# R7FA8M1AH register map
Vendor: Renesas; Series: RA8; File version: 1.2
CPU: CM85 r0p0, little endian, MPU, FPU, VTOR, 4 interrupt priority bits
Registers are 32-bit, read-write, reset 0x0 unless marked. A register's access mark holds for its fields unless they carry their own. Offsets are from the block's base; [hi:lo] are bit positions; {n}, {i} and the like mark numbered series.

## SRAM — SRAM Control
Base 0x40002000
Same registers: SRAM_NS 0x50002000
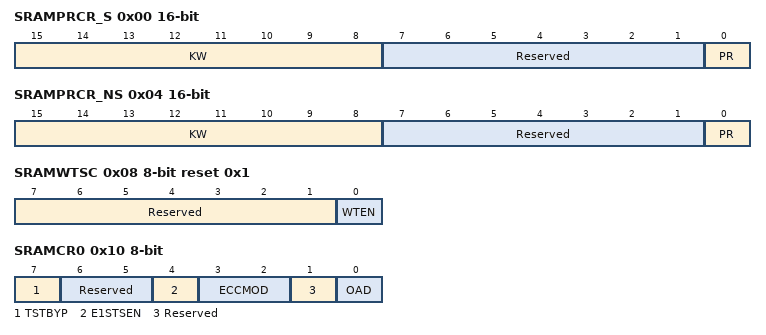
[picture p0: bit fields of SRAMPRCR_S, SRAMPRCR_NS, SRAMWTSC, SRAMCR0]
0x00 SRAMPRCR_S 16-bit — SRAM Protection Control Register for Secure
  [15:8] KW — Write Key Code
  [7:1] Reserved — These bits are read as 0000000. The write value should be 0000000.
  [0] PR — Register Write Control
    0=Accesses to registers are disabled; 1=Accesses to registers are enabled
0x04 SRAMPRCR_NS 16-bit — SRAM Protection Control Register for Non-Secure
  [15:8] KW — Write Key Code
  [7:1] Reserved — These bits are read as 0000000. The write value should be 0000000.
  [0] PR — Register Write Control
    0=Writing to registers are disabled; 1=Writing to registers are enabled
0x08 SRAMWTSC 8-bit reset 0x1 — SRAM Wait State Control Register
  [7:1] Reserved — These bits are read as 0000000. The write value should be 0000000.
  [0] WTEN — wait enable
    0=Do not add wait state in read access cycle to SRAMs; 1=Add wait state in read access cycle to SRAMs
0x10 SRAMCR0 8-bit — SRAM Control Register 0
  [7] TSTBYP — ECC Test Enable / ECC Bypass Select
    0=Disable ECC bypass; 1=Enable ECC bypass
  [6:5] Reserved — These bits are read as 00. The write value should be 00.
  [4] E1STSEN — ECC 1-Bit Error Information Update Enable
    0=Disable updating of 1-bit ECC error information; 1=Enable updating of 1-bit ECC error information
  [3:2] ECCMOD — ECC Operating Mode Select
    0=Disable ECC function; 1=Setting prohibited; 2=Enable ECC function without error checking; 3=Enable ECC function with error checking
  [1] Reserved — This bit is read as 0. The write value should be 0.
  [0] OAD — Operation after detection for 1-bit ECC error detection
    0=Non-maskable interrupt; 1=Reset
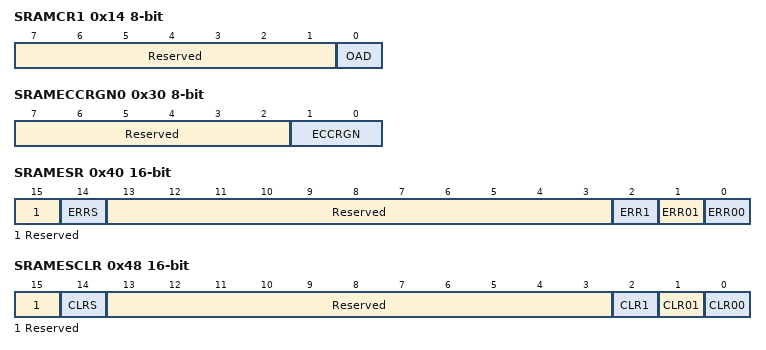
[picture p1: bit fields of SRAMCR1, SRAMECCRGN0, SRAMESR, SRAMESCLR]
0x14 SRAMCR1 8-bit — SRAM Control Register 1
  [7:1] Reserved — These bits are read as 0000000. The write value should be 0000000.
  [0] OAD — Operation after detection for parity error detection
    0=Non maskable interrupt; 1=Reset
0x30 SRAMECCRGN0 8-bit — SRAM0 ECC Region Control Register
  [7:2] Reserved — These bits are read as 000000. The write value should be 000000.
  [1:0] ECCRGN — ECC Region
    0=No ECC Region; 1=0x2200_0000 – 0x2201_FFFF / 0x3200_0000 – 0x3201_FFFF (128KB); 2=0x2200_0000 – 0x2203_FFFF / 0x3200_0000 – 0x3203_FFFF (256KB); 3=0x2200_0000 – 0x2205_FFFF / 0x3200_0000 – 0x3205_FFFF (384KB)
0x40 SRAMESR 16-bit ro — SRAM Error Status Register
  [15] Reserved — This bit is read as 0.
  [14] ERRS — Standby SRAM Parity Error status
    0=Parity error has not occurred; 1=Parity error has occurred
  [13:3] Reserved — These bits are read as 00000000000.
  [2] ERR1 — SRAM1 Parity Error Status
    0=Parity error has not occurred; 1=Parity error has occurred
  [1] ERR01 — SRAM0 2-bit ECC Error Status
    0=2-bit ECC error has not occurred; 1=2-bit ECC error has occurred
  [0] ERR00 — SRAM0 1-bit ECC Error Status
    0=1-bit ECC error has not occurred; 1=1-bit ECC error has occurred
0x48 SRAMESCLR 16-bit — SRAM Error Status Clear Register
  [15] Reserved — This bit is read as 0. The write value should be 0.
  [14] CLRS — Standby SRAM Parity Error Status Clear
    1=Clear Parity error
  [13:3] Reserved — These bits are read as 00000000000. The write value should be 00000000000.
  [2] CLR1 — SRAM1 Parity Error Status Clear
    1=Clear Parity error
  [1] CLR01 — SRAM0 2-bit ECC Error Status Clear
    1=Clear 2-bit ECC error
  [0] CLR00 — SRAM0 1-bit ECC Error Status Clear
    1=Clear 1-bit ECC error
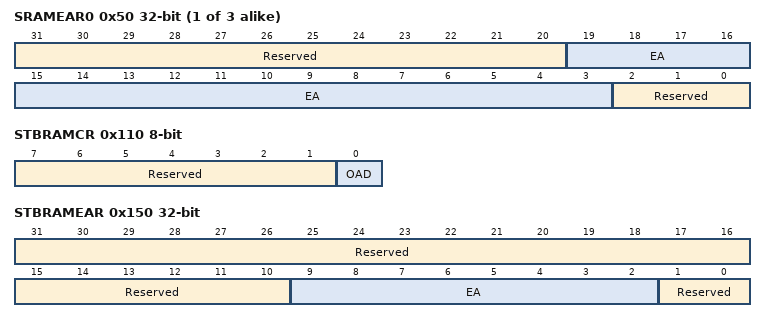
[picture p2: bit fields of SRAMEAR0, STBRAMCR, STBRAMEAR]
{0x50+4i} SRAMEAR{i} (i=0..2) ro — SRAM Error Address Register
  [31:20] Reserved — These bits are read as 000000000000.
  [19:3] EA — SRAM Error Address
  [2:0] Reserved — These bits are read as 000.
0x110 STBRAMCR 8-bit — Standby SRAM Control Register
  [7:1] Reserved — These bits are read as 0000000. The write value should be 0000000.
  [0] OAD — Operation after detection
    0=Non-maskable interrupt; 1=Reset
0x150 STBRAMEAR ro — Standby SRAM Error Address Register
  [31:10] Reserved — These bits are read as 0000000000000000000000.
  [9:2] EA — SRAM Error Address
  [1:0] Reserved — These bits are read as 00.
